# LPC55S16 register map
Vendor: nxp.com; File version: 1.0
CPU: CM33 r2p0, little endian, MPU, FPU, VTOR, 3 interrupt priority bits
Registers are 32-bit, read-write, reset 0x0 unless marked. A register's access mark holds for its fields unless they carry their own. Offsets are from the block's base; [hi:lo] are bit positions; 'fields as' and 'values as' point back to an identical list; <NAME> marks a mode.

## USBPHY — Universal System Bus Physical Layer
Base 0x40038000
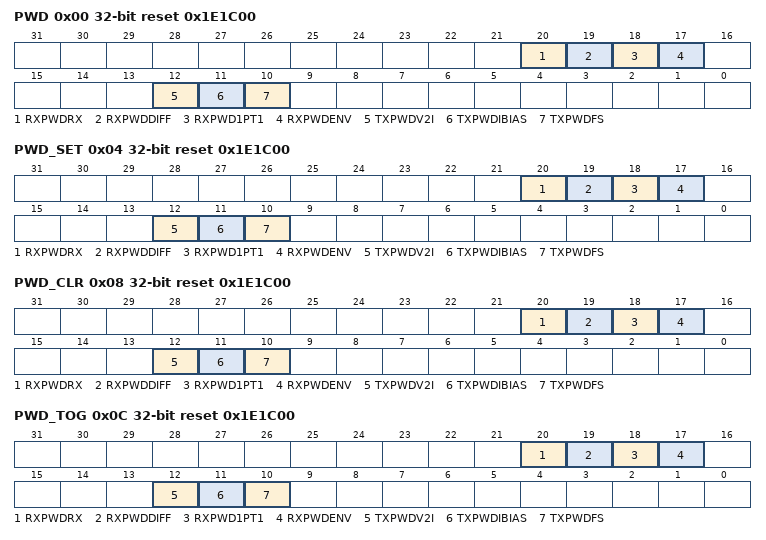
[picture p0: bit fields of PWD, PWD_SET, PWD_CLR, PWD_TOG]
0x00 PWD reset 0x1E1C00 — USB PHY Power-Down Register
  [20] RXPWDRX — This bit will be auto cleared if there is USB wakeup event while ENAUTOCLR_PHY_PWD bit of CTRL is enabled
    0=Normal operation; 1=Power-down the entire USB PHY receiver block except for the full-speed differential receiver
  [19] RXPWDDIFF — Note that this bit will be auto cleared if there is USB wakeup event while ENAUTOCLR_PHY_PWD bit of CTRL is enabled
    0=Normal operation; 1=Power-down the USB high-speed differential receive
  [18] RXPWD1PT1 — Note that this bit will be auto cleared if there is USB wakeup event while ENAUTOCLR_PHY_PWD bit of CTRL is enabled
    0=Normal operation; 1=Power-down the USB full-speed differential receiver
  [17] RXPWDENV — Note that this bit will be auto cleared if there is USB wakeup event while ENAUTOCLR_PHY_PWD bit of CTRL is enabled
    0=Normal operation; 1=Power-down the USB high-speed receiver envelope detector (squelch signal)
  [12] TXPWDV2I — Note that this bit will be auto cleared if there is USB wakeup event while ENAUTOCLR_PHY_PWD bit of CTRL is enabled
    0=Normal operation; 1=Power-down the USB PHY transmit V-to-I converter and the current mirror
  [11] TXPWDIBIAS — Note that this bit will be auto cleared if there is USB wakeup event while ENAUTOCLR_PHY_PWD bit of CTRL is enabled
    0=Normal operation; 1=Power-down the USB PHY current bias block for the transmitter. This bit should be set only when the
  [10] TXPWDFS — Note that this bit will be auto cleared if there is USB wakeup event while ENAUTOCLR_PHY_PWD bit of CTRL is enabled
    0=Normal operation; 1=Power-down the USB full-speed drivers. This turns off the current starvation sources and puts the
0x04 PWD_SET reset 0x1E1C00 — USB PHY Power-Down Register
  fields as PWD
0x08 PWD_CLR reset 0x1E1C00 — USB PHY Power-Down Register
  fields as PWD
0x0C PWD_TOG reset 0x1E1C00 — USB PHY Power-Down Register
  fields as PWD
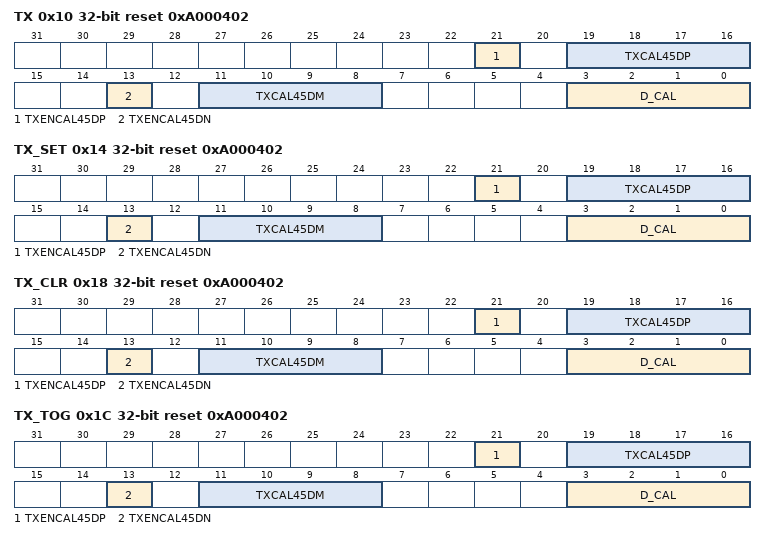
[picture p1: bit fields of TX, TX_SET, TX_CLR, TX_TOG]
0x10 TX reset 0xA000402 — USB PHY Transmitter Control Register
  [21] TXENCAL45DP — Enable resistance calibration on DP.
  [19:16] TXCAL45DP — Decode to trim the nominal 45ohm series termination resistance to the USB_DP output pin
  [13] TXENCAL45DN — Enable resistance calibration on DN.
  [11:8] TXCAL45DM — Decode to trim the nominal 45ohm series termination resistance to the USB_DM output pin
  [3:0] D_CAL — Decode to trim the nominal 17
    0=Maximum current, approximately 19% above nominal; 7=Nominal; 15=Minimum current, approximately 19% below nominal
0x14 TX_SET reset 0xA000402 — USB PHY Transmitter Control Register
  fields as TX
0x18 TX_CLR reset 0xA000402 — USB PHY Transmitter Control Register
  fields as TX
0x1C TX_TOG reset 0xA000402 — USB PHY Transmitter Control Register
  fields as TX
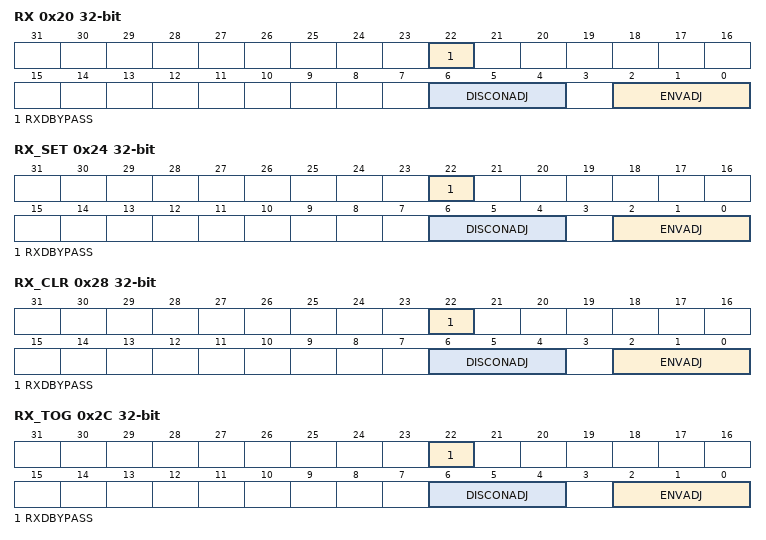
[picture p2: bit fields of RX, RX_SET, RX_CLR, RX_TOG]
0x20 RX — USB PHY Receiver Control Register
  [22] RXDBYPASS — This test mode is intended for lab use only, replace FS differential receiver with DP single ended receiver
    0=Normal operation; 1=Use the output of the USB_DP single-ended receiver in place of the full-speed differential receiver
  [6:4] DISCONADJ — The DISCONADJ field adjusts the trip point for the disconnect detector.
    0=Trip-Level Voltage is 0.56875 V; 1=Trip-Level Voltage is 0.55000 V; 2=Trip-Level Voltage is 0.58125 V; 3=Trip-Level Voltage is 0.60000 V
  [2:0] ENVADJ — The ENVADJ field adjusts the trip point for the envelope detector
    0=Trip-Level Voltage is 0.1000 V; 1=Trip-Level Voltage is 0.1125 V; 2=Trip-Level Voltage is 0.1250 V; 3=Trip-Level Voltage is 0.0875 V
0x24 RX_SET — USB PHY Receiver Control Register
  fields as RX
0x28 RX_CLR — USB PHY Receiver Control Register
  fields as RX
0x2C RX_TOG — USB PHY Receiver Control Register
  fields as RX
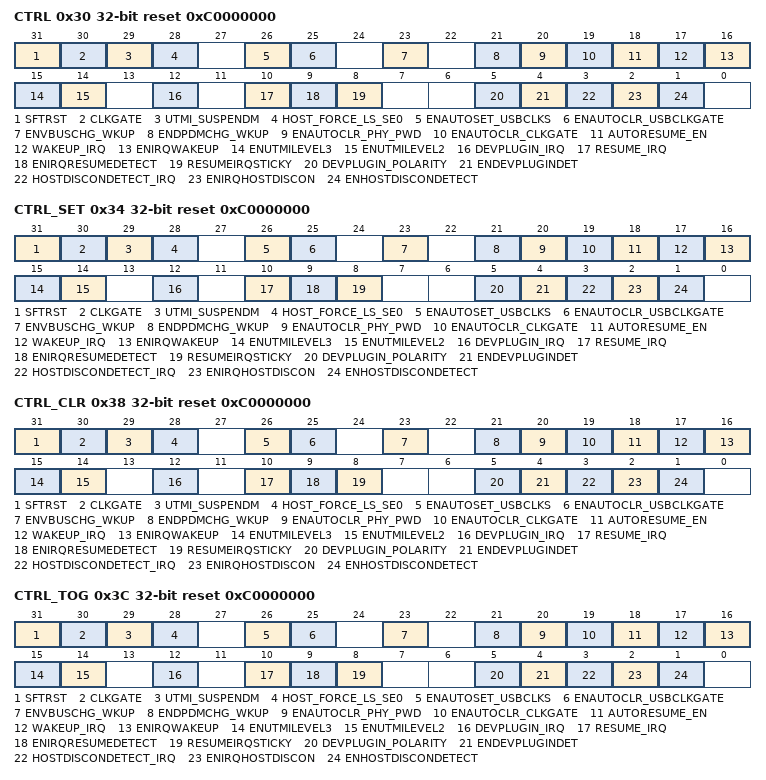
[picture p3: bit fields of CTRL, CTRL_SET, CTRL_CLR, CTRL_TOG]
0x30 CTRL reset 0xC0000000 — USB PHY General Control Register
  [31] SFTRST — Writing a 1 to this bit will soft-reset the PWD, TX, RX, and CTRL registers
  [30] CLKGATE — Gate UTMI Clocks
  [29] UTMI_SUSPENDM — Used by the PHY to indicate a powered-down state
  [28] HOST_FORCE_LS_SE0 — Forces the next FS packet that is transmitted to have a EOP with low-speed timing
  [26] ENAUTOSET_USBCLKS — Enable auto-set of USB clocks: Enables the feature to auto-clear the EN_USB_CLKS register bits in HW_CLKCTRL_PLL1CTRL0/HW_CLKCTRL_P LL1CTRL1 if there is wake-up event on USB0/USB1 while USB0/USB1 is suspended
  [25] ENAUTOCLR_USBCLKGATE — Enable auto-clear USB Clock gate: Enables the feature to auto-clear the USB0_CLKGATE/USB1_CLKGATE register bit in HW_DIGCTL_CTRL if there is wake-up event on USB0/USB1 while USB0/USB1 is suspended
  [23] ENVBUSCHG_WKUP — Enable VBUS change wake-up: Enables the feature to wake-up USB if VBUS is toggled when USB is suspended
  [21] ENDPDMCHG_WKUP — Enable DP DM change wake-up: Not for customer use
  [20] ENAUTOCLR_PHY_PWD — Enables the feature to auto-clear the PWD register bits in PWD if there is wakeup event while USB is suspended
  [19] ENAUTOCLR_CLKGATE — Enables the feature to auto-clear the CLKGATE bit if there is wakeup event while USB is suspended
  [18] AUTORESUME_EN — Enable the auto resume feature, when set, HW will use 32KHz clock to send Resume to respond to the device remote wakeup(for host mode only)
  [17] WAKEUP_IRQ — Wake-up IRQ: Indicates that there is a wak-eup event
  [16] ENIRQWAKEUP — Enable wake-up IRQ: Enables interrupt for the wake-up events.
  [15] ENUTMILEVEL3 — Enables UTMI+ Level 3 operation for the USB HS PHY
  [14] ENUTMILEVEL2 — Enables UTMI+ Level 2 operation for the USB HS PHY
  [12] DEVPLUGIN_IRQ — Indicates that the device is connected
  [10] RESUME_IRQ — Resume IRQ: Indicates that the host is sending a wake-up after suspend
  [9] ENIRQRESUMEDETECT — Enable IRQ Resume detect: Enables interrupt for detection of a non-J state on the USB line
  [8] RESUMEIRQSTICKY — Resume IRQ: Set to 1 will make RESUME_IRQ bit a sticky bit until software clear it
  [5] DEVPLUGIN_POLARITY — Device plugin polarity: For device mode, if this bit is cleared to 0, then it trips the interrupt if the device is plugged in
  [4] ENDEVPLUGINDET — Enables non-standard resistive plugged-in detection This bit field controls connection of nominal 200kohm resistors to both the USB_DP and USB_DM pins as one method of detecting when a USB cable is attached in device mode
    0=Disables 200kohm pullup resistors on USB_DP and USB_DM pins (Default); 1=Enables 200kohm pullup resistors on USB_DP and USB_DM pins
  [3] HOSTDISCONDETECT_IRQ — Indicates that the device has disconnected in High-Speed mode
  [2] ENIRQHOSTDISCON — Enable IRQ for Host disconnect: Enables interrupt for detection of disconnection to Device when in high-speed host mode
  [1] ENHOSTDISCONDETECT — For host mode, enables high-speed disconnect detector
0x34 CTRL_SET reset 0xC0000000 — USB PHY General Control Register
  [31] SFTRST — Writing a 1 to this bit will soft-reset the PWD, TX, RX, and CTRL registers
  [30] CLKGATE — Gate UTMI Clocks
  [29] UTMI_SUSPENDM ro — Used by the PHY to indicate a powered-down state
  [28] HOST_FORCE_LS_SE0 — Forces the next FS packet that is transmitted to have a EOP with low-speed timing
  [26] ENAUTOSET_USBCLKS — Enable auto-set of USB clocks: Enables the feature to auto-clear the EN_USB_CLKS register bits in HW_CLKCTRL_PLL1CTRL0/HW_CLKCTRL_P LL1CTRL1 if there is wake-up event on USB0/USB1 while USB0/USB1 is suspended
  [25] ENAUTOCLR_USBCLKGATE — Enable auto-clear USB Clock gate: Enables the feature to auto-clear the USB0_CLKGATE/USB1_CLKGATE register bit in HW_DIGCTL_CTRL if there is wake-up event on USB0/USB1 while USB0/USB1 is suspended
  [23] ENVBUSCHG_WKUP — Enable VBUS change wake-up: Enables the feature to wake-up USB if VBUS is toggled when USB is suspended
  [21] ENDPDMCHG_WKUP — Enable DP DM change wake-up: Not for customer use
  [20] ENAUTOCLR_PHY_PWD — Enables the feature to auto-clear the PWD register bits in PWD if there is wakeup event while USB is suspended
  [19] ENAUTOCLR_CLKGATE — Enables the feature to auto-clear the CLKGATE bit if there is wakeup event while USB is suspended
  [18] AUTORESUME_EN — Enable the auto resume feature, when set, HW will use 32KHz clock to send Resume to respond to the device remote wakeup(for host mode only)
  [17] WAKEUP_IRQ — Wake-up IRQ: Indicates that there is a wak-eup event
  [16] ENIRQWAKEUP — Enable wake-up IRQ: Enables interrupt for the wake-up events.
  [15] ENUTMILEVEL3 — Enables UTMI+ Level 3 operation for the USB HS PHY
  [14] ENUTMILEVEL2 — Enables UTMI+ Level 2 operation for the USB HS PHY
  [12] DEVPLUGIN_IRQ — Indicates that the device is connected
  [10] RESUME_IRQ — Resume IRQ: Indicates that the host is sending a wake-up after suspend
  [9] ENIRQRESUMEDETECT — Enable IRQ Resume detect: Enables interrupt for detection of a non-J state on the USB line
  [8] RESUMEIRQSTICKY — Resume IRQ: Set to 1 will make RESUME_IRQ bit a sticky bit until software clear it
  [5] DEVPLUGIN_POLARITY — Device plugin polarity: For device mode, if this bit is cleared to 0, then it trips the interrupt if the device is plugged in
  [4] ENDEVPLUGINDET — Enables non-standard resistive plugged-in detection This bit field controls connection of nominal 200kohm resistors to both the USB_DP and USB_DM pins as one method of detecting when a USB cable is attached in device mode
    values as CTRL.ENDEVPLUGINDET
  [3] HOSTDISCONDETECT_IRQ — Indicates that the device has disconnected in High-Speed mode
  [2] ENIRQHOSTDISCON — Enable IRQ for Host disconnect: Enables interrupt for detection of disconnection to Device when in high-speed host mode
  [1] ENHOSTDISCONDETECT — For host mode, enables high-speed disconnect detector
0x38 CTRL_CLR reset 0xC0000000 — USB PHY General Control Register
  fields as CTRL
0x3C CTRL_TOG reset 0xC0000000 — USB PHY General Control Register
  fields as CTRL
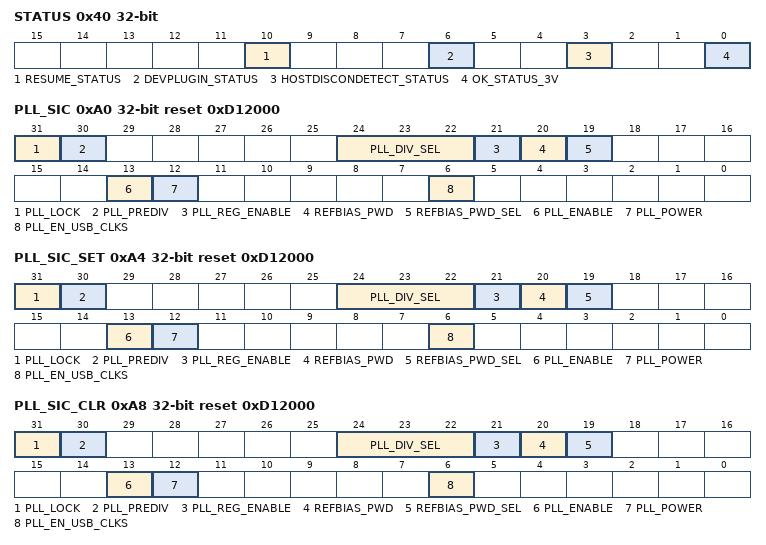
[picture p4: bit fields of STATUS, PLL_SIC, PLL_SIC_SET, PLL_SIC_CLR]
0x40 STATUS — USB PHY Status Register
  [10] RESUME_STATUS ro — Indicates that the host is sending a wake-up after Suspend and has triggered an interrupt.
  [6] DEVPLUGIN_STATUS ro — Status indicator for non-standard resistive plugged-in detection Indicates that the device has been connected on the USB_DP and USB_DM lines using the nonstandard resistive plugged-in detection method controlled by CTRL[4]
    0=No attachment to a USB host is detected; 1=Cable attachment to a USB host is detected
  [3] HOSTDISCONDETECT_STATUS ro — Indicates at the local host (downstream) port that the remote device has disconnected while in High-Speed mode
    0=USB cable disconnect has not been detected at the local host; 1=USB cable disconnect has been detected at the local host
  [0] OK_STATUS_3V ro — Indicates the USB 3v power rails are in range.
0xA0 PLL_SIC reset 0xD12000 — USB PHY PLL Control/Status Register
  [31] PLL_LOCK ro — USB PLL lock status indicator
    0=PLL is not currently locked; 1=PLL is currently locked
  [30] PLL_PREDIV — This is selection between /1 or /2 to expand the range of ref input clock.
  [24:22] PLL_DIV_SEL — This field controls the USB PLL feedback loop divider
    0=Divide by 13; 1=Divide by 15; 2=Divide by 16; 3=Divide by 20; 4=Divide by 22; 5=Divide by 25; 6=Divide by 30; 7=Divide by 240
  [21] PLL_REG_ENABLE — This field controls the USB PLL regulator, set to enable the regulator
  [20] REFBIAS_PWD — Power down the reference bias This bit is only used when REFBIAS_PWD_SEL is set to 1.
  [19] REFBIAS_PWD_SEL — Reference bias power down select.
    0=Selects PLL_POWER to control the reference bias; 1=Selects REFBIAS_PWD to control the reference bias
  [13] PLL_ENABLE — Enables the clock output from the USB PLL
  [12] PLL_POWER — Power up the USB PLL
  [6] PLL_EN_USB_CLKS — Enables the USB clock from PLL to USB PHY
0xA4 PLL_SIC_SET reset 0xD12000 — USB PHY PLL Control/Status Register
  fields as PLL_SIC
0xA8 PLL_SIC_CLR reset 0xD12000 — USB PHY PLL Control/Status Register
  fields as PLL_SIC
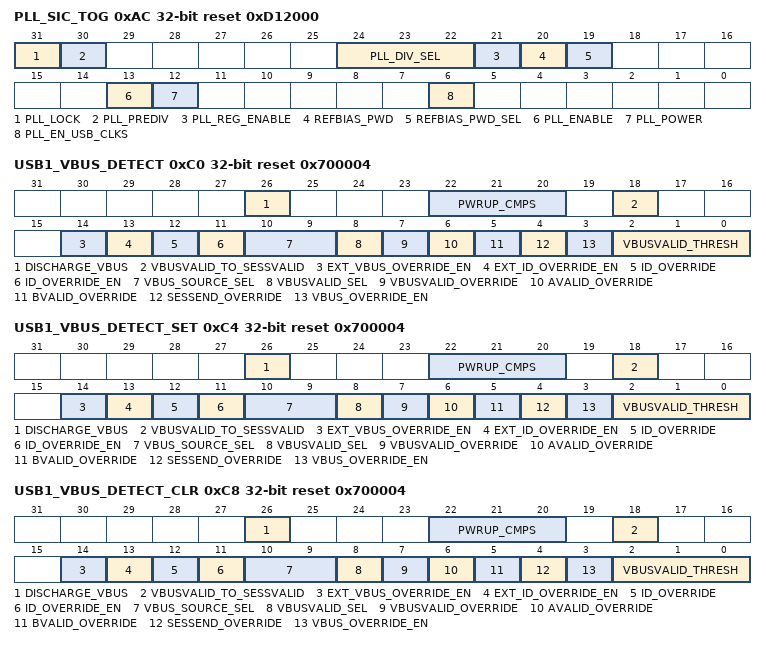
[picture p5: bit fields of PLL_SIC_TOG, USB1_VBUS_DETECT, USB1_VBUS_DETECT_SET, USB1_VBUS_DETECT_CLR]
0xAC PLL_SIC_TOG reset 0xD12000 — USB PHY PLL Control/Status Register
  fields as PLL_SIC
0xC0 USB1_VBUS_DETECT reset 0x700004 — USB PHY VBUS Detect Control Register
  [26] DISCHARGE_VBUS — Controls VBUS discharge resistor This bit field controls a nominal 22kohm resistor between the USB1_VBUS pin and ground
    0=VBUS discharge resistor is disabled (Default); 1=VBUS discharge resistor is enabled
  [22:20] PWRUP_CMPS — Enables the VBUS_VALID comparator: Powers up the comparator used for the VBUS_VALID detector
    0=Powers down the VBUS_VALID comparator; 7=Enables the VBUS_VALID comparator (default)
  [18] VBUSVALID_TO_SESSVALID — Selects the comparator used for VBUS_VALID This bit field controls the comparator used to report the VBUS_VALID results in USB1_VBUS_DETECT[3] between the VBUS_VALID comparator and the Session Valid comparator
    0=Use the VBUS_VALID comparator for VBUS_VALID results; 1=Use the Session End comparator for VBUS_VALID results. The Session End threshold is >0.8V and <4.0V.
  [14] EXT_VBUS_OVERRIDE_EN — Enable VBUS override using the pinmuxed value.
    0=Select the Muxed value chosen using VBUS_OVERRIDE_EN; 1=Select the external VBUS VALID value
  [13] EXT_ID_OVERRIDE_EN — Enable ID override using the pinmuxed value:
    0=Select the Muxed value chosen using ID_OVERRIDE_EN; 1=Select the external ID value
  [12] ID_OVERRIDE — ID override value.
  [11] ID_OVERRIDE_EN — Enable ID override using the register field. This bit is only used if EXT_ID_OVERRIDE_EN = 1'b0.
  [10:9] VBUS_SOURCE_SEL — Selects the source of the VBUS_VALID signal reported to the USB controller This is one of the bit fields that selects the source of the VBUS_VALID signal reported to the USB controller
    0=Use the VBUS_VALID comparator results for signal reported to the USB controller (Default); 1=Use the Session Valid comparator results for signal reported to the USB controller; 2=Use the Session Valid comparator results for signal reported to the USB controller
  [8] VBUSVALID_SEL — Selects the source of the VBUS_VALID signal reported to the USB controller This is one of the bit fields that selects the source of the VBUS_VALID signal reported to the USB controller
    0=Use the VBUS_VALID comparator results for signal reported to the USB controller (Default); 1=Use the VBUS_VALID_3V detector results for signal reported to the USB controller
  [7] VBUSVALID_OVERRIDE — Override value for VBUS_VALID signal sent to USB controller The bit field provides the value for VBUS_VALID reported to the USB controller if the value of USB1_VBUS_DETECT[3] is set to 1'b1
  [6] AVALID_OVERRIDE — Override value for A-Device Session Valid The bit field provides the value for USB1_VBUS_DET_STAT[2] if USB_VBUS_DETECT[3] is set to value 1'b1
  [5] BVALID_OVERRIDE — Override value for B-Device Session Valid The bit field provides the value for USB1_VBUS_DET_STAT[1] if USB_VBUS_DETECT[3] is set to value 1'b1
  [4] SESSEND_OVERRIDE — Override value for SESSEND The bit field provides the value for USB1_VBUS_DET_STAT[0] if USB_VBUS_DETECT[3] is set to value 1'b1
  [3] VBUS_OVERRIDE_EN — VBUS detect signal override enable
    0=Use the results of the internal VBUS_VALID and Session Valid comparators for VBUS_VALID, AVALID, BVALID, and SESSEND (Default); 1=Use the override values for VBUS_VALID, AVALID, BVALID, and SESSEND
  [2:0] VBUSVALID_THRESH — Sets the threshold for the VBUSVALID comparator
    0=4.0V; 1=4.1V; 2=4.2V; 3=4.3V; 4=4.4V(Default); 5=4.5V; 6=4.6V; 7=4.7V
0xC4 USB1_VBUS_DETECT_SET reset 0x700004 — USB PHY VBUS Detect Control Register
  fields as USB1_VBUS_DETECT
0xC8 USB1_VBUS_DETECT_CLR reset 0x700004 — USB PHY VBUS Detect Control Register
  [26] DISCHARGE_VBUS — Controls VBUS discharge resistor This bit field controls a nominal 22kohm resistor between the USB1_VBUS pin and ground
    values as USB1_VBUS_DETECT.DISCHARGE_VBUS
  [22:20] PWRUP_CMPS — Enables the VBUS_VALID comparator: Powers up the comparator used for the VBUS_VALID detector
    values as USB1_VBUS_DETECT.PWRUP_CMPS
  [18] VBUSVALID_TO_SESSVALID — Selects the comparator used for VBUS_VALID This bit field controls the comparator used to report the VBUS_VALID results in USB1_VBUS_DETECT[3] between the VBUS_VALID comparator and the Session Valid comparator
    values as USB1_VBUS_DETECT.VBUSVALID_TO_SESSVALID
  [14] EXT_VBUS_OVERRIDE_EN — Enable VBUS override using the pin muxed value.
    0=Select the muxed value chosen using VBUS_OVERRIDE_EN; 1=Select the external VBUS VALID value
  [13] EXT_ID_OVERRIDE_EN — Enable ID override using the pinmuxed value:
    values as USB1_VBUS_DETECT.EXT_ID_OVERRIDE_EN
  [12] ID_OVERRIDE — ID override value.
  [11] ID_OVERRIDE_EN — Enable ID override using the register field. This bit is only used if EXT_ID_OVERRIDE_EN = 1'b0.
  [10:9] VBUS_SOURCE_SEL — Selects the source of the VBUS_VALID signal reported to the USB controller This is one of the bit fields that selects the source of the VBUS_VALID signal reported to the USB controller
    values as USB1_VBUS_DETECT.VBUS_SOURCE_SEL
  [8] VBUSVALID_SEL — Selects the source of the VBUS_VALID signal reported to the USB controller This is one of the bit fields that selects the source of the VBUS_VALID signal reported to the USB controller
    values as USB1_VBUS_DETECT.VBUSVALID_SEL
  [7] VBUSVALID_OVERRIDE — Override value for VBUS_VALID signal sent to USB controller The bit field provides the value for VBUS_VALID reported to the USB controller if the value of USB1_VBUS_DETECT[3] is set to 1'b1
  [6] AVALID_OVERRIDE — Override value for A-Device Session Valid The bit field provides the value for USB1_VBUS_DET_STAT[2] if USB_VBUS_DETECT[3] is set to value 1'b1
  [5] BVALID_OVERRIDE — Override value for B-Device Session Valid The bit field provides the value for USB1_VBUS_DET_STAT[1] if USB_VBUS_DETECT[3] is set to value 1'b1
  [4] SESSEND_OVERRIDE — Override value for SESSEND The bit field provides the value for USB1_VBUS_DET_STAT[0] if USB_VBUS_DETECT[3] is set to value 1'b1
  [3] VBUS_OVERRIDE_EN — VBUS detect signal override enable
    values as USB1_VBUS_DETECT.VBUS_OVERRIDE_EN
  [2:0] VBUSVALID_THRESH — Sets the threshold for the VBUSVALID comparator
    values as USB1_VBUS_DETECT.VBUSVALID_THRESH
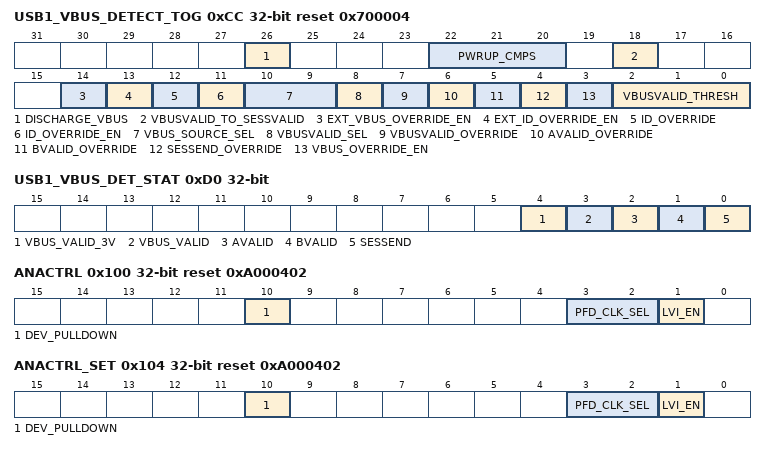
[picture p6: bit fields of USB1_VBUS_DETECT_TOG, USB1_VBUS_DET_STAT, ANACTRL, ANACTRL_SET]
0xCC USB1_VBUS_DETECT_TOG reset 0x700004 — USB PHY VBUS Detect Control Register
  [26] DISCHARGE_VBUS — Controls VBUS discharge resistor This bit field controls a nominal 22kohm resistor between the USB1_VBUS pin and ground
    values as USB1_VBUS_DETECT.DISCHARGE_VBUS
  [22:20] PWRUP_CMPS — Enables the VBUS_VALID comparator Powers up the comparator used for the VBUS_VALID detector
    values as USB1_VBUS_DETECT.PWRUP_CMPS
  [18] VBUSVALID_TO_SESSVALID — Selects the comparator used for VBUS_VALID This bit field controls the comparator used to report the VBUS_VALID results in USB1_VBUS_DETECT[3] between the VBUS_VALID comparator and the Session Valid comparator
    values as USB1_VBUS_DETECT.VBUSVALID_TO_SESSVALID
  [14] EXT_VBUS_OVERRIDE_EN — Enable VBUS override using the pin muxed value.
    values as USB1_VBUS_DETECT.EXT_VBUS_OVERRIDE_EN
  [13] EXT_ID_OVERRIDE_EN — Enable ID override using the pin muxed value.
    0=Select the muxed value chosen using ID_OVERRIDE_EN; 1=Select the external ID value
  [12] ID_OVERRIDE — ID override value.
  [11] ID_OVERRIDE_EN — Enable ID override using the register field. This bit is only used if EXT_ID_OVERRIDE_EN = 1'b0.
  [10:9] VBUS_SOURCE_SEL — Selects the source of the VBUS_VALID signal reported to the USB controller This is one of the bit fields that selects the source of the VBUS_VALID signal reported to the USB controller
    values as USB1_VBUS_DETECT.VBUS_SOURCE_SEL
  [8] VBUSVALID_SEL — Selects the source of the VBUS_VALID signal reported to the USB controller This is one of the bit fields that selects the source of the VBUS_VALID signal reported to the USB controller
    values as USB1_VBUS_DETECT.VBUSVALID_SEL
  [7] VBUSVALID_OVERRIDE — Override value for VBUS_VALID signal sent to USB controller The bit field provides the value for VBUS_VALID reported to the USB controller if the value of USB1_VBUS_DETECT[3] is set to 1'b1
  [6] AVALID_OVERRIDE — Override value for A-Device Session Valid The bit field provides the value for USB1_VBUS_DET_STAT[2] if USB_VBUS_DETECT[3] is set to value 1'b1
  [5] BVALID_OVERRIDE — Override value for B-Device Session Valid The bit field provides the value for USB1_VBUS_DET_STAT[1] if USB_VBUS_DETECT[3] is set to value 1'b1
  [4] SESSEND_OVERRIDE — Override value for SESSEND The bit field provides the value for USB1_VBUS_DET_STAT[0] if USB_VBUS_DETECT[3] is set to value 1'b1
  [3] VBUS_OVERRIDE_EN — VBUS detect signal override enable
    values as USB1_VBUS_DETECT.VBUS_OVERRIDE_EN
  [2:0] VBUSVALID_THRESH — Sets the threshold for the VBUSVALID comparator
    values as USB1_VBUS_DETECT.VBUSVALID_THRESH
0xD0 USB1_VBUS_DET_STAT ro — USB PHY VBUS Detector Status Register
  [4] VBUS_VALID_3V — VBUS_VALID_3V detector status The VBUS_VALID_3V detector has a lower threshold for the voltage on the USB1_VBUS pin than either the Session Valid or VBUS_VALID comparators
    0=VBUS voltage is below VBUS_VALID_3V threshold; 1=VBUS voltage is above VBUS_VALID_3V threshold
  [3] VBUS_VALID — VBUS voltage status This bit field shows the result of VBUS_VALID detection for the USB1_VBUS pin
    0=VBUS is below the comparator threshold; 1=VBUS is above the comparator threshold
  [2] AVALID — A-Device Session Valid status A-Device Session Valid status, determined by the Session Valid comparator
    0=The VBUS voltage is below the Session Valid threshold; 1=The VBUS voltage is above the Session Valid threshold
  [1] BVALID — B-Device Session Valid status B-Device Session Valid status, determined by the Session Valid comparator
    values as AVALID
  [0] SESSEND — Session End indicator Session End status, value inverted from Session Valid comparator
    0=The VBUS voltage is above the Session Valid threshold; 1=The VBUS voltage is below the Session Valid threshold
0x100 ANACTRL reset 0xA000402 — USB PHY Analog Control Register
  [10] DEV_PULLDOWN — Setting this field to 1'b1 will enable the 15kohm pulldown resistors on both USB_DP and USB_DM pins
    0=The 15kohm nominal pulldowns on the USB_DP and USB_DM pinsare disabled in device mode; 1=The 15kohm nominal pulldowns on the USB_DP and USB_DM pinsare enabled in device mode
  [3:2] PFD_CLK_SEL — For normal USB operation, this bit field must remain at value 2'b00.
  [1] LVI_EN — Vow voltage detector enable bit.
0x104 ANACTRL_SET reset 0xA000402 — USB PHY Analog Control Register
  fields as ANACTRL
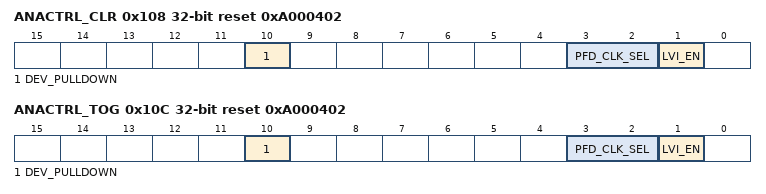
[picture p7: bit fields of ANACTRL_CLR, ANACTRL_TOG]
0x108 ANACTRL_CLR reset 0xA000402 — USB PHY Analog Control Register
  fields as ANACTRL
0x10C ANACTRL_TOG reset 0xA000402 — USB PHY Analog Control Register
  fields as ANACTRL
